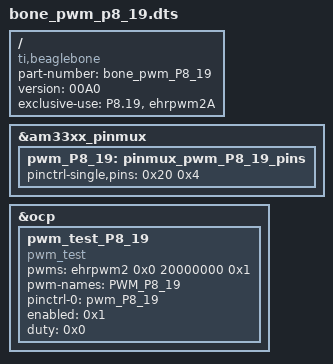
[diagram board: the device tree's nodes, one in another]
/dts-v1/;

/ {
	compatible = "ti,beaglebone", "ti,beaglebone-black";
	part-number = "bone_pwm_P8_19";
	version = "00A0";
	exclusive-use = "P8.19", "ehrpwm2A";

	fragment@0 {
		target = <&am33xx_pinmux>;

		__overlay__ {

			pwm_P8_19:pinmux_pwm_P8_19_pins {
				pinctrl-single,pins = <0x20 0x4>;
				linux,phandle = <0x1>;
				phandle = <0x1>;
			};
		};
	};

	fragment@1 {
		target = <&ocp>;

		__overlay__ {

			pwm_test_P8_19 {
				compatible = "pwm_test";
				pwms = <&ehrpwm2 0x0 20000000 0x1>;
				pwm-names = "PWM_P8_19";
				pinctrl-names = "default";
				pinctrl-0 = <&pwm_P8_19>;
				enabled = <0x1>;
				duty = <0x0>;
				status = "okay";
			};
		};
	};

	__symbols__ {
		pwm_P8_19 = "/fragment@0/__overlay__/pinmux_pwm_P8_19_pins";
	};

	__fixups__ {
		am33xx_pinmux = "/fragment@0:target:0";
		ocp = "/fragment@1:target:0";
		ehrpwm2 = "/fragment@1/__overlay__/pwm_test_P8_19:pwms:0";
	};

	__local_fixups__ {
		fixup = "/fragment@1/__overlay__/pwm_test_P8_19:pinctrl-0:0";
	};
};
